# MK53DZ10 register map
Vendor: Freescale Semiconductor, Inc.; Series: Kinetis_K; File version: 1.6
CPU: CM4 r0p1, little endian, no MPU, no FPU, VTOR, 4 interrupt priority bits
Registers are 32-bit, read-write, reset 0x0 unless marked. A register's access mark holds for its fields unless they carry their own. Offsets are from the block's base; [hi:lo] are bit positions; {n}, {i} and the like mark numbered series.

## RNG — Random Number Generator
Base 0x400A0000; register names take the prefix RNG_
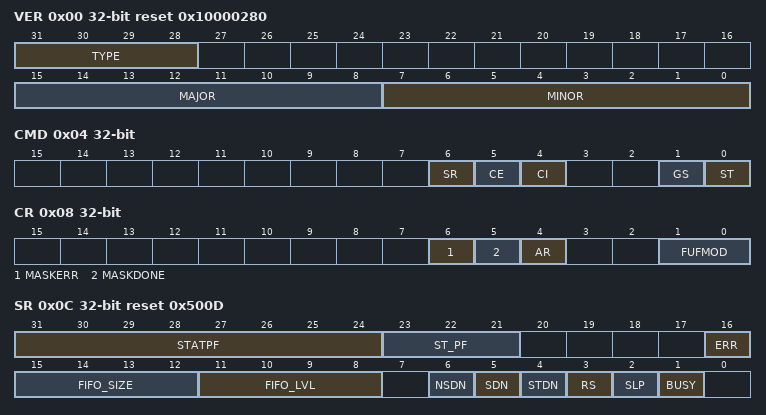
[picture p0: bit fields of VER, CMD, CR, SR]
0x00 VER ro reset 0x10000280 — RNGB Version ID Register
  [31:28] TYPE — Random number generator type
    0=RNGA; 1=RNGB (This is the type used in this module); 2=RNGC
  [15:8] MAJOR — Major version number.
  [7:0] MINOR — Minor version number.
0x04 CMD — RNGB Command Register
  [6] SR wo — Software reset.
    0=Do not perform a software reset; 1=Software reset
  [5] CE wo — Clear error.
    0=Do not clear errors and interrupt; 1=Clear errors and interrupt
  [4] CI wo — Clear interrupt.
    0=Do not clear interrupt; 1=Clear interrupt
  [1] GS — Generate seed.
    0=Not in seed generation mode; 1=Generate seed mode
  [0] ST — Self test.
    0=Not in self test mode; 1=Self test mode
0x08 CR — RNGB Control Register
  [6] MASKERR — Mask error interrupt.
    0=No mask applied; 1=Mask applied to the error interrupt
  [5] MASKDONE — Mask done interrupt.
    0=No mask applied; 1=Mask applied
  [4] AR — Auto-reseed.
    0=Do not enable automatic reseeding; 1=Enable automatic reseeding
  [1:0] FUFMOD — FIFO underflow response mode.
    0=Return all zeros and set RNG_ESR[FUFE]; 1=Return all zeros and set RNG_ESR[FUFE]; 2=Generate bus transfer error; 3=Generate interrupt and return all zeros (Overrides RNG_CR[MASKERR])
0x0C SR ro reset 0x500D — RNGB Status Register
  [31:24] STATPF — Statistics test pass fail.
    0=Pass; 1=Fail
  [23:21] ST_PF — Self Test Pass Fail.
    0=Pass; 1=Fail
  [16] ERR — Error.
    0=No error; 1=Error detected
  [15:12] FIFO_SIZE
  [11:8] FIFO_LVL — FIFO level.
  [6] NSDN — New seed done.
  [5] SDN — Seed done.
    0=Seed generation process not complete; 1=Completed seed generation since the last reset
  [4] STDN — Self test done.
    0=Self test not complete; 1=Completed a self test since the last reset
  [3] RS — Reseed needed.
    0=RNGB does not need to be reseeded; 1=RNGB needs to be reseeded
  [2] SLP — Sleep.
    0=RNGB is not in sleep mode; 1=RNGB is in sleep mode
  [1] BUSY
    0=Not busy; 1=Busy
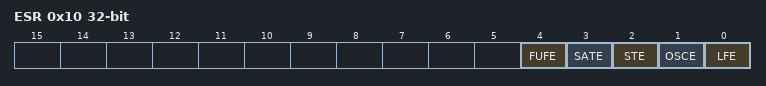
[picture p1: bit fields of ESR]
0x10 ESR ro — RNGB Error Status Register
  [4] FUFE — FIFO underflow error
    0=FIFO underflow has not occurred; 1=FIFO underflow has occurred
  [3] SATE — Statistical test error.
    0=RNGB has not failed the statistical tests; 1=RNGB has failed the statistical tests during initialization
  [2] STE — Self test error.
    0=RNGB has not failed self test; 1=RNGB has failed self test
  [1] OSCE — Oscillator error.
    0=RNG oscillator is working properly; 1=Problem detected with the RNG oscillator
  [0] LFE — Linear feedback shift register (LFSR) error.
    0=LFSRs are working properly; 1=LFSR failure has occurred
0x14 OUT ro — RNGB Output FIFO
  [31:0] RANDOUT — Random Output

## DAC0 — 12-Bit Digital-to-Analog Converter
Base 0x400CC000; register names take the prefix DAC0_
{0x0+2i} DAT{i}L (i=0..15) 8-bit — DAC Data Low Register
  [7:0] DATA
{0x1+2i} DAT{i}H (i=0..15) 8-bit — DAC Data High Register
  [3:0] DATA
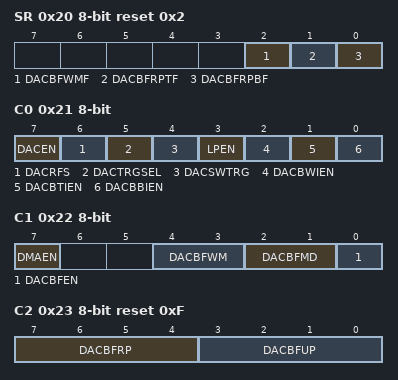
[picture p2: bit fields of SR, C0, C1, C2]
0x20 SR 8-bit reset 0x2 — DAC Status Register
  [2] DACBFWMF — DAC buffer watermark flag
    0=The DAC buffer read pointer has not reached the watermark level; 1=The DAC buffer read pointer has reached the watermark level
  [1] DACBFRPTF — DAC buffer read pointer top position flag
    0=The DAC buffer read pointer is not zero; 1=The DAC buffer read pointer is zero
  [0] DACBFRPBF — DAC buffer read pointer bottom position flag
    0=The DAC buffer read pointer is not equal to the DACBFUP; 1=The DAC buffer read pointer is equal to the DACBFUP
0x21 C0 8-bit — DAC Control Register
  [7] DACEN — DAC enable
    0=The DAC system is disabled; 1=The DAC system is enabled
  [6] DACRFS — DAC Reference Select
    0=The DAC selets DACREF_1 as the reference voltage; 1=The DAC selets DACREF_2 as the reference voltage
  [5] DACTRGSEL — DAC trigger select
    0=The DAC hardware trigger is selected; 1=The DAC software trigger is selected
  [4] DACSWTRG wo — DAC software trigger
    0=The DAC soft trigger is not valid; 1=The DAC soft trigger is valid
  [3] LPEN — DAC low power control
    0=high power mode; 1=low power mode
  [2] DACBWIEN — DAC buffer watermark interrupt enable
    0=The DAC buffer watermark interrupt is disabled; 1=The DAC buffer watermark interrupt is enabled
  [1] DACBTIEN — DAC buffer read pointer top flag interrupt enable
    0=The DAC buffer read pointer top flag interrupt is disabled; 1=The DAC buffer read pointer top flag interrupt is enabled
  [0] DACBBIEN — DAC buffer read pointer bottom flag interrupt enable
    0=The DAC buffer read pointer bottom flag interrupt is disabled; 1=The DAC buffer read pointer bottom flag interrupt is enabled
0x22 C1 8-bit — DAC Control Register 1
  [7] DMAEN — DMA enable select
    0=DMA disabled; 1=DMA enabled. When DMA enabled, DMA request will be generated by original interrupts. And interrupts will not be presented on this module at the same time.
  [4:3] DACBFWM — DAC buffer watermark select
    0=1 word; 1=2 words; 2=3 words; 3=4 words
  [2:1] DACBFMD — DAC buffer work mode select
    0=Normal Mode; 1=Swing Mode; 2=One-Time Scan Mode
  [0] DACBFEN — DAC buffer enable
    0=Buffer read pointer disabled. The converted data is always the first word of the buffer.; 1=Buffer read pointer enabled. The converted data is the word that the read pointer points to. It means converted data can be from any word of the buffer.
0x23 C2 8-bit reset 0xF — DAC Control Register 2
  [7:4] DACBFRP — DAC buffer read pointer
  [3:0] DACBFUP — DAC buffer upper limit

## DAC1 — 12-Bit Digital-to-Analog Converter
Base 0x400CD000; register names take the prefix DAC1_
Registers as DAC0.

## Notices in the file
Redistribution and use in source and binary forms, with or without modification,
are permitted provided that the following conditions are met:
o Redistributions of source code must retain the above copyright notice, this list
of conditions and the following disclaimer.
o Redistributions in binary form must reproduce the above copyright notice, this
list of conditions and the following disclaimer in the documentation and/or
other materials provided with the distribution.
o Neither the name of Freescale Semiconductor, Inc. nor the names of its
contributors may be used to endorse or promote products derived from this
software without specific prior written permission.
THIS SOFTWARE IS PROVIDED BY THE COPYRIGHT HOLDERS AND CONTRIBUTORS "AS IS" AND
ANY EXPRESS OR IMPLIED WARRANTIES, INCLUDING, BUT NOT LIMITED TO, THE IMPLIED
WARRANTIES OF MERCHANTABILITY AND FITNESS FOR A PARTICULAR PURPOSE ARE
DISCLAIMED. IN NO EVENT SHALL THE COPYRIGHT HOLDER OR CONTRIBUTORS BE LIABLE FOR
ANY DIRECT, INDIRECT, INCIDENTAL, SPECIAL, EXEMPLARY, OR CONSEQUENTIAL DAMAGES
(INCLUDING, BUT NOT LIMITED TO, PROCUREMENT OF SUBSTITUTE GOODS OR SERVICES;
LOSS OF USE, DATA, OR PROFITS; OR BUSINESS INTERRUPTION) HOWEVER CAUSED AND ON
ANY THEORY OF LIABILITY, WHETHER IN CONTRACT, STRICT LIABILITY, OR TORT
(INCLUDING NEGLIGENCE OR OTHERWISE) ARISING IN ANY WAY OUT OF THE USE OF THIS
SOFTWARE, EVEN IF ADVISED OF THE POSSIBILITY OF SUCH DAMAGE.
